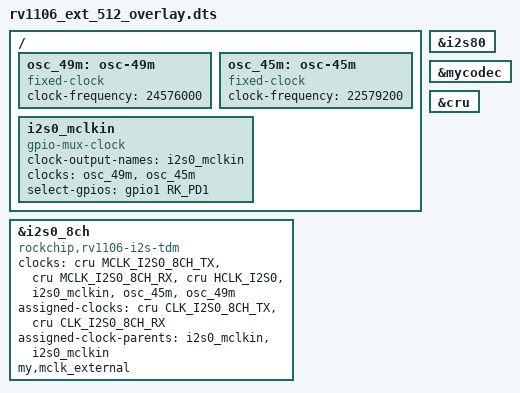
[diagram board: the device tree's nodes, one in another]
/dts-v1/;
/plugin/;

#include "rv1106.dtsi"
#include "rv1106-pinctrl.dtsi"

/ {
    fragment@0 {
        target-path = "/";

        __overlay__ {
            /* Активация внешних часов */
            osc_49m: osc-49m {
                compatible = "fixed-clock";
                #clock-cells = <0>;
                clock-frequency = <24576000>; // 24.576 МГц
            };

            osc_45m: osc-45m {
                compatible = "fixed-clock";
                #clock-cells = <0>;
                clock-frequency = <22579200>; // 22.5792 МГц
            };

            i2s0_mclkin: i2s0_mclkin {
                compatible = "gpio-mux-clock";
                #clock-cells = <0>;
                clock-output-names = "i2s0_mclkin";
                clocks = <&osc_49m>, <&osc_45m>;
                select-gpios = <&gpio1 RK_PD1 GPIO_ACTIVE_HIGH>; // GPIO для выбора источника
            };
        };
    };

    fragment@1 {
        target = <&i2s0_8ch>;

        __overlay__ {
            /* Переопределение I2S на внешние часы */
            compatible = "rockchip,rv1106-i2s-tdm";
            clocks = <&cru MCLK_I2S0_8CH_TX>, <&cru MCLK_I2S0_8CH_RX>, <&cru HCLK_I2S0>,
                     <&i2s0_mclkin>, <&osc_45m>, <&osc_49m>;
            clock-names = "mclk_tx", "mclk_rx", "hclk", "mclk_ext", "clk_44", "clk_48";
            assigned-clocks = <&cru CLK_I2S0_8CH_TX>, <&cru CLK_I2S0_8CH_RX>;
            assigned-clock-parents = <&i2s0_mclkin>, <&i2s0_mclkin>;
            my,mclk_external; // Флаг использования внешнего MCLK
            status = "okay"; // Активировать устройство
        };
    };

    fragment@2 {
        target = <&i2s80>;

        __overlay__ {
            /* Удаление mclk-fs для внешнего MCLK */
            /delete-property/ simple-audio-card,mclk-fs;
        };
    };

    fragment@3 {
        target = <&mycodec>;

        __overlay__ {
            status = "okay"; // Активация кодеков
        };
    };

    fragment@4 {
        target = <&cru>;

        __overlay__ {
            /* Удаление PLL-настроек, если конфликтуют */
            /delete-node/ assigned-clocks;
            /delete-node/ assigned-clock-parents;
        };
    };
};

